# STM32MP25_CA35 register map
File version: 1.3
Registers are 32-bit, read-write, reset 0x0 unless marked. A register's access mark holds for its fields unless they carry their own. Offsets are from the block's base; [hi:lo] are bit positions; lines under a group give offsets from that group; {n}, {i} and the like mark numbered series; 'fields as' and 'values as' point back to an identical list.

## GICH — GICH address block description
Base 0x4AC40000
Same registers: GICH_S 0x5AC40000
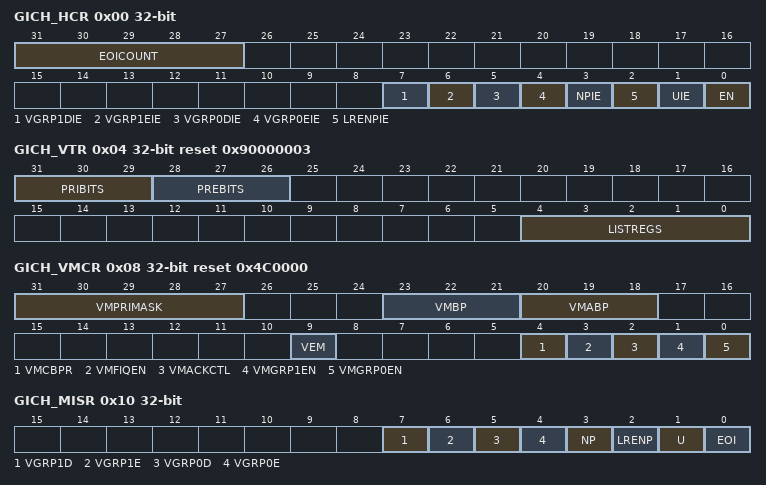
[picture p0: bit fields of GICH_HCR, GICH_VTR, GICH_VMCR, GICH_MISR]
0x00 GICH_HCR — GICH hypervisor control register
  [31:27] EOICOUNT — End-of-interrupt counter
  [7] VGRP1DIE — Virtual machine disable group 1 interrupt enable
  [6] VGRP1EIE — Virtual machine enable group 1 interrupt enable
  [5] VGRP0DIE — Virtual machine disable group 0 interrupt enable
  [4] VGRP0EIE — Virtual machine enable group 0interrupt enable
  [3] NPIE — No pending interrupt enable
  [2] LRENPIE — List register entry not present interrupt enable
  [1] UIE — Underflow interrupt enable.
  [0] EN — Global enable bit for the virtual CPU interface
0x04 GICH_VTR ro reset 0x90000003 — GICH VGIC type register
  [31:29] PRIBITS — Priority bits
  [28:26] PREBITS — Preemption bits
  [4:0] LISTREGS — List registers
0x08 GICH_VMCR reset 0x4C0000 — GICH virtual machine control register
  [31:27] VMPRIMASK — Alias of GICV_PMR.PRIORITY
  [23:21] VMBP — Alias of GICV_BPR.BINARY_POINT
  [20:18] VMABP — Alias of GICV_ABPR.BINARY_POINT.
  [9] VEM — Alias of GICV_CTLR.EOIMODE
  [4] VMCBPR — Alias of GICV_CTLR.CBPR
  [3] VMFIQEN — Alias of GICV_CTLR.FIQEN
  [2] VMACKCTL — Alias of GICV_CTLR.ACKCTL
  [1] VMGRP1EN — Alias of GICV_CTLR.ENABLEGRP1
  [0] VMGRP0EN — Alias of GICV_CTLR.ENABLEGRP0
0x10 GICH_MISR ro — GICH maintenance interrupt status register
  [7] VGRP1D — Disabled group 1 maintenance interrupt
  [6] VGRP1E — Enabled group 1 maintenance interrupt
  [5] VGRP0D — Disabled group 0 maintenance interrupt
  [4] VGRP0E — Enabled group 0 maintenance interrupt
  [3] NP — No pending maintenance interrupt
  [2] LRENP — List register entry not present maintenance interrupt
  [1] U — Underflow maintenance interrupt
  [0] EOI — End of interrupt maintenance interrupt
0x20 GICH_EISR0 ro (reset mask 0xF) — GICH end of interrupt status register
  [31:0] EISR0 — End of interrupt status
0x30 GICH_ELSR0 ro reset 0xF (reset mask 0xF) — GICH empty list status register
  [31:0] ELSR0 — Empty list status
0xF0 GICH_APR0 — GICH active priority register
  [31:0] APR0 — Active priority
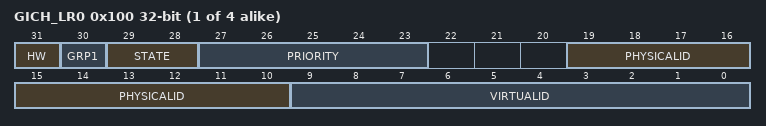
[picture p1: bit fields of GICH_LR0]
{0x100+4i} GICH_LR{i} (i=0..3) — GICH list register {i}
  [31] HW — Hardware interrupt
  [30] GRP1 — This bit indicates whether this virtual interrupt is a group 1 virtual interrupt.
  [29:28] STATE — State of the interrupt
  [27:23] PRIORITY — Priority of the interrupt
  [19:10] PHYSICALID
  [9:0] VIRTUALID

## HDP — HDP address block description
Base 0x44090000
Same registers: HDP_S 0x54090000
0x00 HDP_CTRL — HDP control register
  [0] EN — HDP enable (valid if enabled in BSEC)
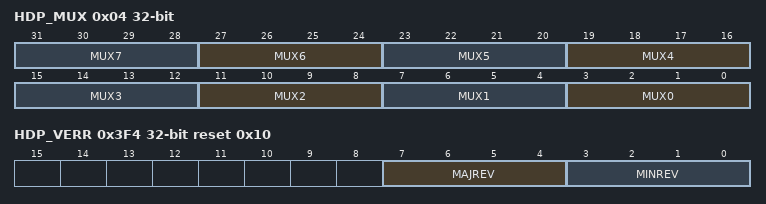
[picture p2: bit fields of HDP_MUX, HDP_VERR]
0x04 HDP_MUX — HDP multiplexer control register
  [4n+3:4n] MUX{n} (n=0..7) — Selection of the HDPy output among the 16 available signals
0x10 HDP_VAL ro — HDP read back value register
  [7:0] HDPVAL — Value of the HDP signals
0x14 HDP_GPOSET wo — HDP general purpose output set register
  [7:0] HDPGPOSET — When a bit is written to 1, the corresponding HDP GPO is set. Writing a bit to 0 has no effect.
0x18 HDP_GPOCLR wo — HDP general purpose output clear register
  [7:0] HDPGPOCLR — When a bit is written to 1, the corresponding HDP GPO is cleared. Writing a bit to 0 has no effect.
0x1C HDP_GPOVAL — HDP general purpose output value register
  [7:0] HDPGPOVAL — When written, this bit field defines the value of the HDP GPO. When read, this bit field provides the current GPO value.
0x3F4 HDP_VERR ro reset 0x10 — HDP version register
  [7:4] MAJREV — HDP major revision
  [3:0] MINREV — HDP minor revision
0x3F8 HDP_IPIDR ro reset 0x30002 — HDP identification register
  [31:0] ID — HDP identifier
0x3FC HDP_SIDR ro reset 0xA3C5DD01 — HDP size identification register
  [31:0] SID — Size identifier

## SERC — SERC register block
Base 0x44080000
Same registers: SERC_S 0x54080000
{0x0+4i} SERC_IER{i} (i=0..5) — SERC interrupt enable register {i}
  [31:0] PDRIE — Power-down or reset interrupt enable for peripheral y Sets the bit to unmask access to power-down or reset events from the peripheral y.
    0=power-down or reset access event from peripheral y does not generate an interrupt (masked); 1=power-down or reset access event from peripheral y generates an interrupt (unmasked)
{0x40+4i} SERC_ISR{i} ro (i=0..4) — SERC interrupt status register {i}
  [31:0] PDRS — Power-down or reset interrupt status for peripheral y The collector sets this bit when a bus_ilac is collected for peripheral y.
    0=no power-down or reset event recorded for this peripheral; 1=a power-down or reset access event has been reported from this peripheral
0x54 SERC_ISR5 ro — SERC interrupt status register 5
  [31:0] PDRS — Power-down or reset clear flag for peripheral y The collector sets this bit when a bus_ilac is collected for peripheral y.
    values as SERC_ISR0.PDRS
{0x80+4i} SERC_ICR{i} wo (i=0..5) — SERC interrupt clear register {i}
  [31:0] PDRC — Power-down or reset clear flag for peripheral y When set, this write-only bit clears the status flag of the illegal access event y set in SERC_ISR{i} register.
    0=PDRCy flag status is not affected; 1=PDRCy flag status is cleared in SERC_ISR{i} register
0x100 SERC_ENABLE
  [0] SERFEN — Enable the SERF framework. When the SERF is enabled, an access to a target under reset or clocked off is detected; a functional error response is given back on the IP bus, an illegal access is reported to the SERC, and an interrupt is fired according to the SERC registers configuration. When the SERF is disabled, an access to a target under reset or clocked off is not detected.
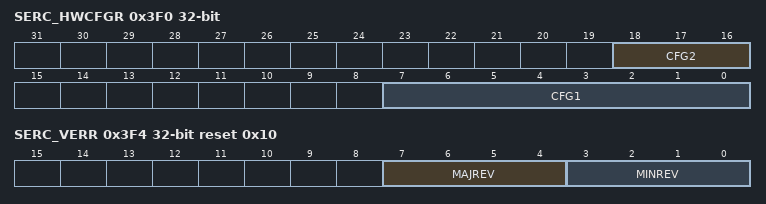
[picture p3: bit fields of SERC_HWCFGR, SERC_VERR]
0x3F0 SERC_HWCFGR ro (reset mask 0xFFF0FF00) — SERC hardware configuration register
  [18:16] CFG2 — NUM_RESYNC_FLOPS, number of resynchronization flops when receiving a bus_ilac information in the SERC clock domain.
  [7:0] CFG1 — NUM_ILAC, number of illegal accesses input pins configured for this instance of the collector.
0x3F4 SERC_VERR ro reset 0x10 — SERC version register
  [7:4] MAJREV — Major revision
  [3:0] MINREV — Minor revision
0x3F8 SERC_IPIDR ro reset 0x1001F0 — SERC identification register
  [31:0] ID — IP identification code
0x3FC SERC_SIDR ro reset 0xA3C5DD01 — SERC size identification register
  [31:0] SID — Size identification code (1 Kbyte)

## Notices in the file
Copyright (c) 2025 STMicroelectronics.
SPDX-License-Identifier: Apache-2.0
Licensed under the Apache License, Version 2.0 (the "License");
you may not use this file except in compliance with the License.
You may obtain a copy of the License at
http://www.apache.org/licenses/LICENSE-2.0
Unless required by applicable law or agreed to in writing, software
distributed under the License is distributed on an "AS IS" BASIS,
WITHOUT WARRANTIES OR CONDITIONS OF ANY KIND, either express or implied.
See the License for the specific language governing permissions and
limitations under the License.
